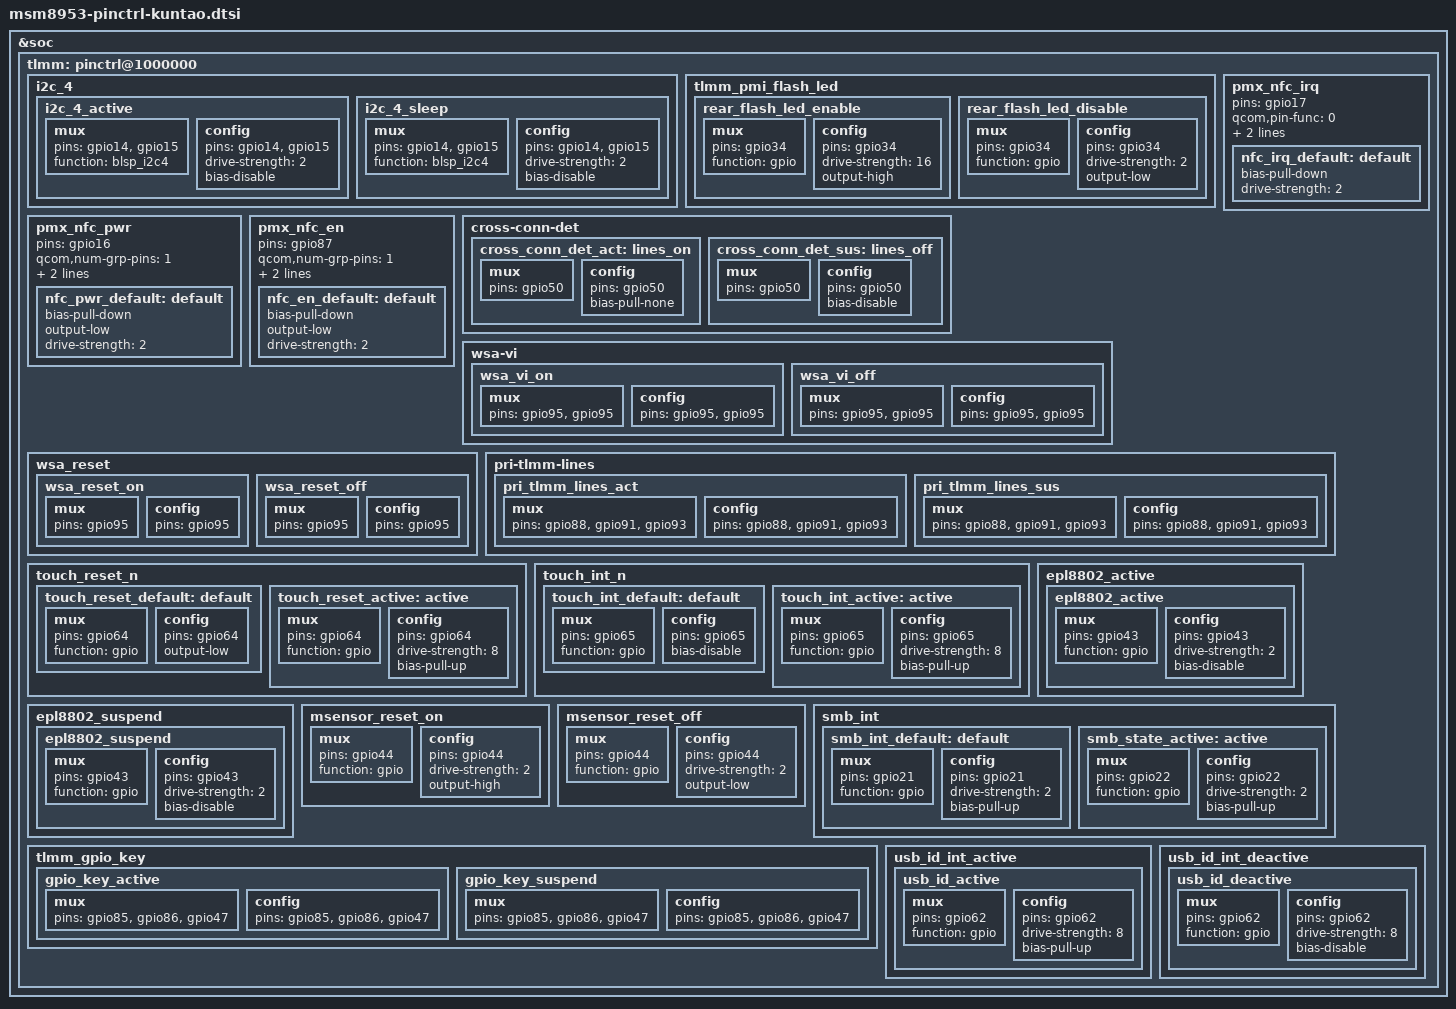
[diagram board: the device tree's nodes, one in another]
/*
 * Copyright (c) 2015-2016, The Linux Foundation. All rights reserved.
 *
 * This program is free software; you can redistribute it and/or modify
 * it under the terms of the GNU General Public License version 2 and
 * only version 2 as published by the Free Software Foundation.
 *
 * This program is distributed in the hope that it will be useful,
 * but WITHOUT ANY WARRANTY; without even the implied warranty of
 * MERCHANTABILITY or FITNESS FOR A PARTICULAR PURPOSE.  See the
 * GNU General Public License for more details.
 */

#include "../msm8953-pinctrl.dtsi"

&soc {
	tlmm: pinctrl@1000000 {
		/delete-node/ cam_sensor_front_default;
		/delete-node/ cam_sensor_front_sleep;
		/delete-node/ cam_sensor_mclk2_default;
		/delete-node/ cam_sensor_mclk2_sleep;

		i2c_4 {
			i2c_4_active: i2c_4_active {
				/* active state */
				mux {
					pins = "gpio14", "gpio15";
					function = "blsp_i2c4";
				};

				config {
					pins = "gpio14", "gpio15";
					drive-strength = <2>; /* 2 MA */
					bias-disable; /* No PULL */
				};
			};

			i2c_4_sleep: i2c_4_sleep {
				/* suspended state */
				mux {
					pins = "gpio14", "gpio15";
					function = "blsp_i2c4";
				};

				config {
					pins = "gpio14", "gpio15";
					drive-strength = <2>; /* 2 MA */
					bias-disable; /* No PULL */
				};
			};
		};

		tlmm_pmi_flash_led {
			rear_flash_led_enable: rear_flash_led_enable {
				mux {
					pins = "gpio34";
					function = "gpio";
				};

				config {
					pins = "gpio34";
					drive-strength = <16>;
					output-high;
				};
			};

			rear_flash_led_disable: rear_flash_led_disable {
				mux {
					pins = "gpio34";
					function = "gpio";
				};

				config {
					pins = "gpio34";
					drive-strength = <2>;
					output-low;
				};
			};
		};

		pmx_nfc_irq {
			pins = "gpio17";
			qcom,pin-func = <0>;
			qcom,num-grp-pins = <1>;
			label = "nfc_irq";

			nfc_irq_default: default {
				bias-pull-down;
				drive-strength = <2>;
			};
		};

		pmx_nfc_pwr {
			pins = "gpio16";
			qcom,num-grp-pins = <1>;
			qcom,pin-func = <0>;
			label = "nfc_pwr";

			nfc_pwr_default: default {
				bias-pull-down;
				output-low;
				drive-strength = <2>;
			};
		};

		pmx_nfc_en {
			pins = "gpio87";
			qcom,num-grp-pins = <1>;
			qcom,pin-func = <0>;
			label = "nfc_en";

			nfc_en_default: default {
				bias-pull-down;
				output-low;
				drive-strength = <2>;
			};
		};

		cross-conn-det {
			cross_conn_det_act: lines_on {
				mux {
					pins = "gpio50";
				};

				config {
					pins = "gpio50";
					bias-pull-none;
				};
			};

			cross_conn_det_sus: lines_off {
				mux {
					pins = "gpio50";
				};

				config {
					pins = "gpio50";
					bias-disable;
				};
			};
		};

		/* WSA VI sense */
		wsa-vi {
			wsa_vi_on: wsa_vi_on {
				mux {
					pins = "gpio95", "gpio95";
				};

				config {
					pins = "gpio95", "gpio95";
				};
			};

			wsa_vi_off: wsa_vi_off {
				mux {
					pins = "gpio95", "gpio95";
				};

				config {
					pins = "gpio95", "gpio95";
				};
			};
		};

		/* WSA Reset */
		wsa_reset {
			wsa_reset_on: wsa_reset_on {
				mux {
					pins = "gpio95";
				};

				config {
					pins = "gpio95";
				};
			};

			wsa_reset_off: wsa_reset_off {
				mux {
					pins = "gpio95";
				};

				config {
					pins = "gpio95";
				};
			};
		};

		pri-tlmm-lines {
			pri_tlmm_lines_act: pri_tlmm_lines_act {
				mux {
					pins = "gpio88", "gpio91", "gpio93";
				};

				config {
					pins = "gpio88", "gpio91", "gpio93";
				};
			};

			pri_tlmm_lines_sus: pri_tlmm_lines_sus {
				mux {
					pins = "gpio88", "gpio91", "gpio93";
				};

				config {
					pins = "gpio88", "gpio91", "gpio93";
				};
			};
		};

		touch_reset_n {
			touch_reset_default: default {
				mux {
					pins = "gpio64";
					function = "gpio";
				};

				config {
					pins = "gpio64";
					output-low;
				};
			};

			touch_reset_active: active {
				mux {
					pins = "gpio64";
					function = "gpio";
				};

				config {
					pins = "gpio64";
					drive-strength = <8>;
					bias-pull-up; /* pull-up */
				};
			};
		};

		touch_int_n {
			touch_int_default: default {
				mux {
					pins = "gpio65";
					function = "gpio";
				};

				config {
					pins = "gpio65";
					bias-disable;
				};
			};

			touch_int_active: active {
				mux {
					pins = "gpio65";
					function = "gpio";
				};

				config {
					pins = "gpio65";
					drive-strength = <8>;
					bias-pull-up; /* pull-up */
				};
			};
		};

		epl8802_active {
			epl8802_active: epl8802_active {
				mux {
					pins = "gpio43";
					function = "gpio";
				};

				config {
					pins = "gpio43";
					drive-strength = <2>;
					bias-disable;
				};
			};
		};

		epl8802_suspend {
			epl8802_suspend: epl8802_suspend {
				mux {
					pins = "gpio43";
					function = "gpio";
				};

				config {
					pins = "gpio43";
					drive-strength = <2>;
					bias-disable;
				};
			};
		};

		msensor_reset_on: msensor_reset_on {
			mux {
				pins = "gpio44";
				function = "gpio";
			};

			config {
				pins = "gpio44";
				drive-strength = <2>; /* 2 MA */
				output-high;
			};
		};

		msensor_reset_off: msensor_reset_off {
			mux {
				pins = "gpio44";
				function = "gpio";
			};

			config {
				pins = "gpio44";
				drive-strength = <2>; /* 2 MA */
				output-low;
			};
		};

		smb_int {
			smb_int_default: default {
				mux {
					pins = "gpio21";
					function = "gpio";
				};

				config {
					pins = "gpio21";
					drive-strength = <2>;
					bias-pull-up;
				};
			};

			smb_state_active: active {
				mux {
					pins = "gpio22";
					function = "gpio";
				};

				config {
					pins = "gpio22";
					drive-strength = <2>;
					bias-pull-up; /* pull-up */
				};
			};
		};

		tlmm_gpio_key {
			gpio_key_active: gpio_key_active {
				mux {
					pins = "gpio85", "gpio86", "gpio47";
				};

				config {
					pins = "gpio85", "gpio86", "gpio47";
				};
			};

			gpio_key_suspend: gpio_key_suspend {
				mux {
					pins = "gpio85", "gpio86", "gpio47";
				};

				config {
					pins = "gpio85", "gpio86", "gpio47";
				};
			};
		};

		usb_id_int_active {
			usb_id_active: usb_id_active {
				mux {
					pins = "gpio62";
					function = "gpio";
				};

				config {
					pins = "gpio62";
					drive-strength = <8>;
					bias-pull-up;
				};
			};
		};

		usb_id_int_deactive {
			usb_id_deactive: usb_id_deactive {
				mux {
					pins = "gpio62";
					function = "gpio";
				};

				config {
					pins = "gpio62";
					drive-strength = <8>;
					bias-disable;
				};
			};
		};
	};
};
